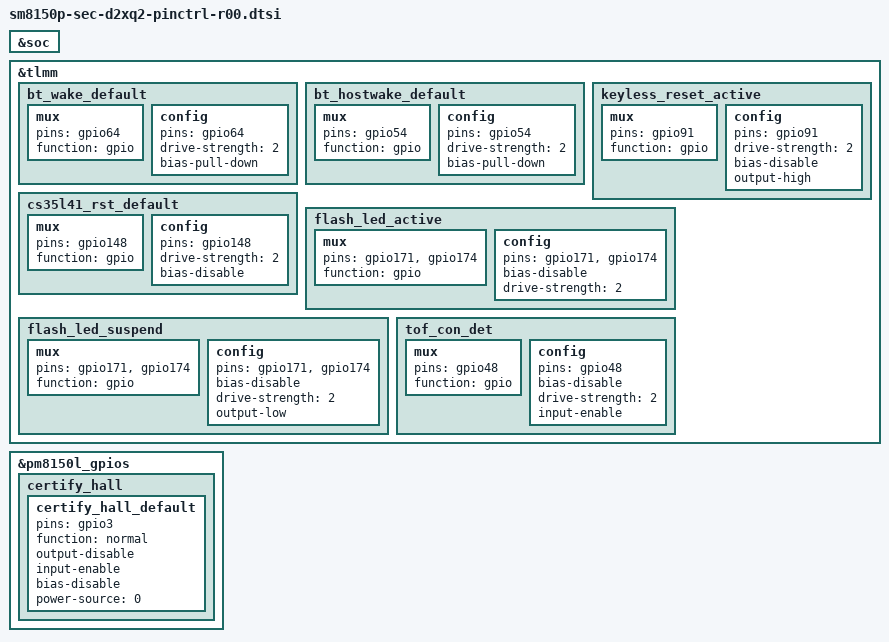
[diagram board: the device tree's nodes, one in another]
/* Copyright (c) 2016-2017, The Linux Foundation. All rights reserved.
 *
 * This program is free software; you can redistribute it and/or modify
 * it under the terms of the GNU General Public License version 2 and
 * only version 2 as published by the Free Software Foundation.
 *
 * This program is distributed in the hope that it will be useful,
 * but WITHOUT ANY WARRANTY; without even the implied warranty of
 * MERCHANTABILITY or FITNESS FOR A PARTICULAR PURPOSE.  See the
 * GNU General Public License for more details.
 */

#include "sm8150p-sec-d2xq2-pinctrl-common.dtsi"

&soc {
	/* tlmm: pinctrl@03400000 { }; */
};

/delete-node/ &keyless_reset_active;	

&tlmm {
	bt_wake_default: bt_wake_default {
		mux {
			pins = "gpio64";
			function = "gpio";
		};
		config {
			pins = "gpio64";
			drive-strength = <2>;
			bias-pull-down;
		};
	};
	bt_hostwake_default: bt_hostwake_default {
		mux {
			pins = "gpio54";
			function = "gpio";
		};
		config {
			pins = "gpio54";
			drive-strength = <2>;
			bias-pull-down;
		};
	};

	keyless_reset_active: keyless_reset_active {
		mux {
			pins = "gpio91";
			function = "gpio";
		};
		config {
			pins = "gpio91";
			drive-strength = <2>;   /* 16 mA */
			bias-disable;
			output-high;
		};
	};

	cs35l41_rst_default: cs35l41_rst_default {
		mux {
			pins = "gpio148";
			function = "gpio";
		};
		config {
			pins = "gpio148";
			drive-strength = <2>; /* 2 MA */
			bias-disable; /* No PULL */
		};
	};
	
	flash_led_active: flash_led_active {
		mux {
			pins = "gpio171","gpio174";
			function = "gpio";
		};

		config {
			pins = "gpio171","gpio174";
			bias-disable; /* No PULL */
			drive-strength = <2>; /* 2 MA */
		};
	};

	flash_led_suspend: flash_led_suspend {
		mux {
			pins = "gpio171","gpio174";
			function = "gpio";
		};

		config {
			pins = "gpio171","gpio174";
			bias-disable; /* No PULL */
			drive-strength = <2>; /* 2 MA */
			output-low;
		};
	};
	tof_con_det: tof_con_det {
		mux {
			pins = "gpio48";
			function = "gpio";
		};

		config {
			pins = "gpio48";
			bias-disable; /* No PULL */
			drive-strength = <2>; /* 2 MA */
			input-enable;
		};
	};
};

&pm8150l_gpios {
	certify_hall {
		certify_hall_default: certify_hall_default {
			pins = "gpio3";
			function = "normal";
			output-disable;
			input-enable;
			bias-disable;
			power-source = <0>;
		};
	};
};
